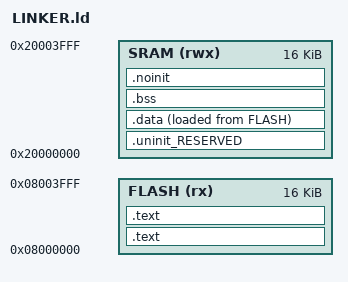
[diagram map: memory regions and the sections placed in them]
/*
 *  Created on: 18 ���� 2015 �.
 *      Author: RLeonov
 *      Just for some tasty booter :)
 */

MEMORY
{
  FLASH (rx)  : ORIGIN = 0x08000000, LENGTH = 0x4000 /* JUST IN CASE: 16K bytes */
  SRAM  (rwx) : ORIGIN = 0x20000000, LENGTH = 0x4000 /* JUST IN CASE: 16K bytes */
}

/* Define a symbol for the top of each memory region */
  __TOP_FLASH = 0x08000000 + 0x4000;
  __TOP_SRAM  = 0x20000000 + 0x4000;

SECTIONS
{
    /* MAIN TEXT SECTION */
    .text : ALIGN(4)
    {
        FILL(0xff)
        __vectors_start__ = ABSOLUTE(.) ;
        KEEP(*(.isr_vector))
        /* Global Section Table */
        . = ALIGN(4) ; 
        __section_table_start = .;
        __data_section_table = .;
        LONG(LOADADDR(.data));
        LONG(    ADDR(.data));
        LONG(  SIZEOF(.data));
        __data_section_table_end = .;
        __bss_section_table = .;
        LONG(    ADDR(.bss));
        LONG(  SIZEOF(.bss));
        __bss_section_table_end = .;
        __section_table_end = . ;
        /* End of Global Section Table */

        *(.after_vectors*)
    } > FLASH

    .text : ALIGN(4)    
    {
        *(.text*)
        *(.rodata .rodata.* .constdata .constdata.*)
        . = ALIGN(4);
    } > FLASH
    
    _etext = .;
        
    /* MAIN DATA SECTION */
    .uninit_RESERVED : ALIGN(4)
    {
        KEEP(*(.bss.$RESERVED*))
        . = ALIGN(4) ;
        _end_uninit_RESERVED = .;
    } > SRAM
    
    /* Main DATA section (Ram) */
    .data : ALIGN(4)
    {
       FILL(0xff)
       _data = . ;
       *(vtable)
       *(.ramfunc*)
       *(.data*)
       . = ALIGN(4) ;
       _edata = . ;
    } > SRAM AT > FLASH
    
    /* MAIN BSS SECTION */
    .bss : ALIGN(4)
    {
        _bss = .;
        *(.bss*)
        *(COMMON)
        . = ALIGN(4) ;
        _ebss = .;
        PROVIDE(end = .);
    } > SRAM
    
    /* DEFAULT NOINIT SECTION */
    .noinit (NOLOAD): ALIGN(4)
    {
        _noinit = .;
        *(.noinit*) 
         . = ALIGN(4) ;
        _end_noinit = .;
    } > SRAM

    PROVIDE(_pvHeapStart = DEFINED(__user_heap_base) ? __user_heap_base : .);
    PROVIDE(_vStackTop = DEFINED(__user_stack_top) ? __user_stack_top : __TOP_SRAM - 0);
 }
